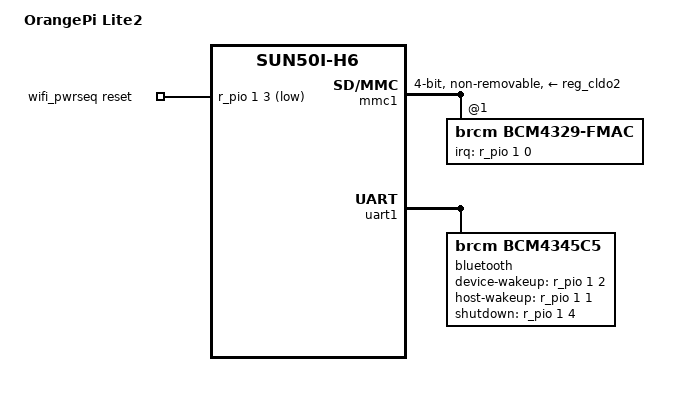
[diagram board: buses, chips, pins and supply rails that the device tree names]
#include "sun50i-h6-orangepi.dtsi"
/ {
	model = "OrangePi Lite2";
	compatible = "xunlong,orangepi-lite2", "allwinner,sun50i-h6";
	aliases {
		serial1 = &uart1;  
	};
	wifi_pwrseq: wifi_pwrseq {
		compatible = "mmc-pwrseq-simple";
		clocks = <&rtc CLK_OSC32K_FANOUT>;
		clock-names = "ext_clock";
		reset-gpios = <&r_pio 1 3 GPIO_ACTIVE_LOW>;  
		post-power-on-delay-ms = <200>;
	};
};
&mmc1 {
	vmmc-supply = <&reg_cldo2>;
	vqmmc-supply = <&reg_bldo3>;
	mmc-pwrseq = <&wifi_pwrseq>;
	bus-width = <4>;
	non-removable;
	status = "okay";
	brcm: sdio-wifi@1 {
		reg = <1>;
		compatible = "brcm,bcm4329-fmac";
		interrupt-parent = <&r_pio>;
		interrupts = <1 0 IRQ_TYPE_LEVEL_LOW>;	 
		interrupt-names = "host-wake";
	};
};
&reg_cldo2 {
	regulator-always-on;
};
&reg_cldo3 {
	regulator-always-on;
};
&uart1 {
	pinctrl-names = "default";
	pinctrl-0 = <&uart1_pins>, <&uart1_rts_cts_pins>;
	uart-has-rtscts;
	status = "okay";
	bluetooth {
		compatible = "brcm,bcm4345c5";
		clocks = <&rtc CLK_OSC32K_FANOUT>;
		clock-names = "lpo";
		device-wakeup-gpios = <&r_pio 1 2 GPIO_ACTIVE_HIGH>;  
		host-wakeup-gpios = <&r_pio 1 1 GPIO_ACTIVE_HIGH>;  
		shutdown-gpios = <&r_pio 1 4 GPIO_ACTIVE_HIGH>;  
		max-speed = <1500000>;
	};
};
